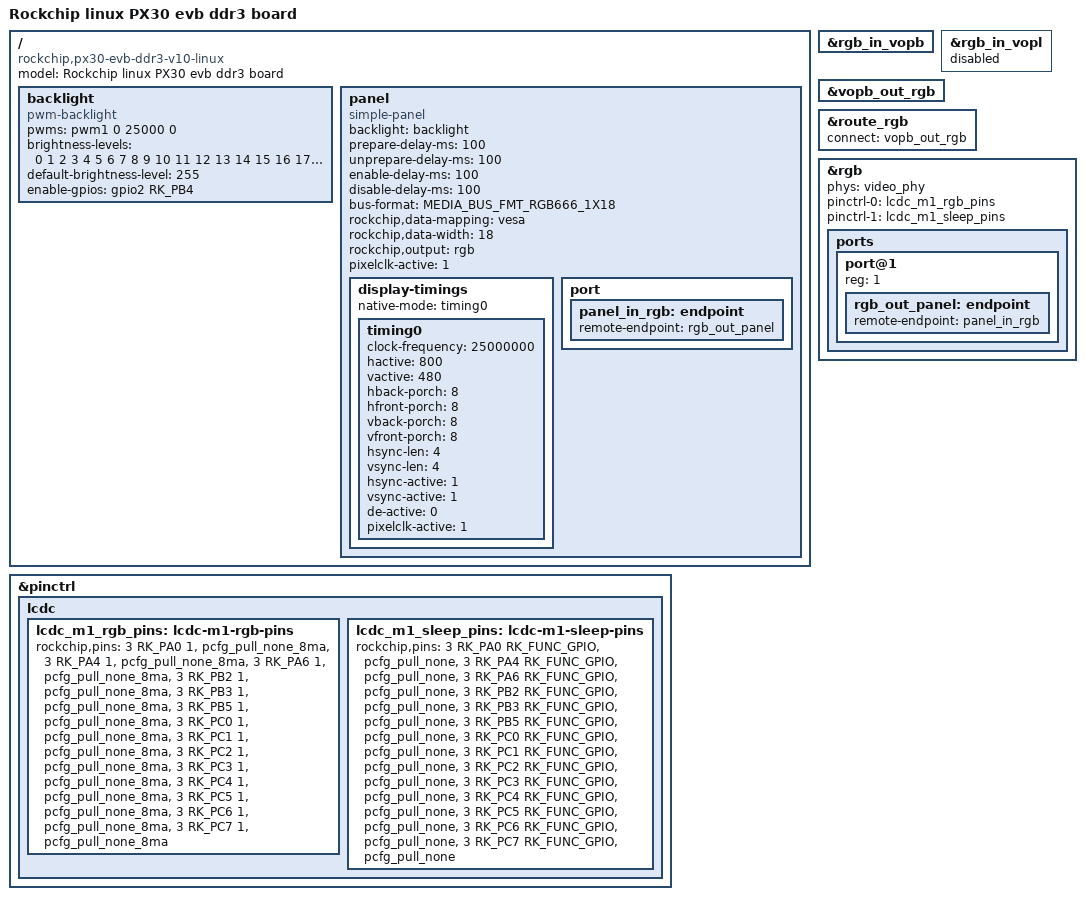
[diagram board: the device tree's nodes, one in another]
// SPDX-License-Identifier: (GPL-2.0+ OR MIT)
/*
 * Copyright (c) 2021 Fuzhou Rockchip Electronics Co., Ltd
 */

/ {
	model = "Rockchip linux PX30 evb ddr3 board";
	compatible = "rockchip,px30-evb-ddr3-v10-linux", "rockchip,px30";

	/delete-node/ test-power;

    backlight: backlight {
        compatible = "pwm-backlight";
        pwms = <&pwm1 0 25000 0>;
        brightness-levels = <
              0   1   2   3   4   5   6   7
              8   9  10  11  12  13  14  15
             16  17  18  19  20  21  22  23
             24  25  26  27  28  29  30  31
             32  33  34  35  36  37  38  39
             40  41  42  43  44  45  46  47
             48  49  50  51  52  53  54  55
             56  57  58  59  60  61  62  63
             64  65  66  67  68  69  70  71
             72  73  74  75  76  77  78  79
             80  81  82  83  84  85  86  87
             88  89  90  91  92  93  94  95
             96  97  98  99 100 101 102 103
            104 105 106 107 108 109 110 111
            112 113 114 115 116 117 118 119
            120 121 122 123 124 125 126 127
            128 129 130 131 132 133 134 135
            136 137 138 139 140 141 142 143
            144 145 146 147 148 149 150 151
            152 153 154 155 156 157 158 159
            160 161 162 163 164 165 166 167
            168 169 170 171 172 173 174 175
            176 177 178 179 180 181 182 183
            184 185 186 187 188 189 190 191
            192 193 194 195 196 197 198 199
            200 201 202 203 204 205 206 207
            208 209 210 211 212 213 214 215
            216 217 218 219 220 221 222 223
            224 225 226 227 228 229 230 231
            232 233 234 235 236 237 238 239
            240 241 242 243 244 245 246 247
            248 249 250 251 252 253 254 255>;
        default-brightness-level = <255>;
        enable-gpios = <&gpio2 RK_PB4 GPIO_ACTIVE_HIGH>;
    };

	//-----------------------RK050HR18-----------------------------
	 panel:panel {
	 	status = "okay";
	 	compatible ="simple-panel";
	 	backlight = <&backlight>;
	 	//enable-gpios = <&gpio0 RK_PC0 GPIO_ACTIVE_LOW>;
	 	//reset-gpios = <&gpio3 RK_PD1 GPIO_ACTIVE_LOW>;
	 	prepare-delay-ms = <100>;
	 	unprepare-delay-ms = <100>;
	 	enable-delay-ms = <100>;
	 	disable-delay-ms = <100>;
	 	bus-format = <MEDIA_BUS_FMT_RGB666_1X18>;
	 	rockchip,data-mapping = "vesa";
	 	rockchip,data-width = <18>;
	 	rockchip,output = "rgb";
	 	pixelclk-active = <1>;

	 	display-timings {
	 		native-mode = <&timing0>;

	 		timing0: timing0 {
	 			clock-frequency = <25000000>;
	 			hactive = <800>;
	 			vactive = <480>;
	 			hback-porch = <8>;
	 			hfront-porch = <8>;
	 			vback-porch = <8>;
	 			vfront-porch = <8>;
	 			hsync-len = <4>;
	 			vsync-len = <4>;
	 			hsync-active = <1>;
	 			vsync-active = <1>;
	 			de-active = <0>;
	 			pixelclk-active = <1>;
	 		};
	 	};

	 	port {
	 		panel_in_rgb: endpoint {
	 			remote-endpoint = <&rgb_out_panel>;
	 		};
	 	};
	 };

	//-----------------------RK050HR18-----------------------------
};

&rgb_in_vopb{
	status = "okay";
};

&rgb_in_vopl{
	status = "disabled";
};

&vopb_out_rgb {
	status = "okay";
};

&route_rgb {                   
    connect = <&vopb_out_rgb>;
    status = "okay";
};

&rgb {
	status = "okay";
    phys = <&video_phy>;
    phy-names = "phy";
    pinctrl-names = "default", "sleep";
    pinctrl-0 = <&lcdc_m1_rgb_pins>;
    pinctrl-1 = <&lcdc_m1_sleep_pins>;

	ports {
		port@1 {
			reg = <1>;

			rgb_out_panel: endpoint {              
				remote-endpoint = <&panel_in_rgb>;
			};
		};
	};
};

&pinctrl {
    lcdc {
        lcdc_m1_rgb_pins: lcdc-m1-rgb-pins {
            rockchip,pins =
                <3 RK_PA0 1 &pcfg_pull_none_8ma>,   /* LCDC_DCLK */
                <3 RK_PA4 1 &pcfg_pull_none_8ma>,   /* LCDC_D0 */
                <3 RK_PA6 1 &pcfg_pull_none_8ma>,   /* LCDC_D2 */
                <3 RK_PB2 1 &pcfg_pull_none_8ma>,   /* LCDC_D6 */
                <3 RK_PB3 1 &pcfg_pull_none_8ma>,   /* LCDC_D7 */
                <3 RK_PB5 1 &pcfg_pull_none_8ma>,   /* LCDC_D9 */
                <3 RK_PC0 1 &pcfg_pull_none_8ma>,   /* LCDC_D12 */
                <3 RK_PC1 1 &pcfg_pull_none_8ma>,   /* LCDC_D13 */
                <3 RK_PC2 1 &pcfg_pull_none_8ma>,   /* LCDC_D14 */
                <3 RK_PC3 1 &pcfg_pull_none_8ma>,   /* LCDC_D15 */
                <3 RK_PC4 1 &pcfg_pull_none_8ma>,   /* LCDC_D16 */
                <3 RK_PC5 1 &pcfg_pull_none_8ma>,   /* LCDC_D17 */
                <3 RK_PC6 1 &pcfg_pull_none_8ma>,   /* LCDC_D18 */
                <3 RK_PC7 1 &pcfg_pull_none_8ma>;   /* LCDC_D19 */
//                <3 RK_PD0 1 &pcfg_pull_none_8ma>,   /* LCDC_D20 */
//                <3 RK_PD1 1 &pcfg_pull_none_8ma>,   /* LCDC_D21 */
//                <3 RK_PD2 1 &pcfg_pull_none_8ma>,   /* LCDC_D22 */
//                <3 RK_PD3 1 &pcfg_pull_none_8ma>;   /* LCDC_D23 */
        };

        lcdc_m1_sleep_pins: lcdc-m1-sleep-pins {
            rockchip,pins =
                <3 RK_PA0 RK_FUNC_GPIO &pcfg_pull_none>,    /* LCDC_DCLK */
                <3 RK_PA4 RK_FUNC_GPIO &pcfg_pull_none>,    /* LCDC_D0 */
                <3 RK_PA6 RK_FUNC_GPIO &pcfg_pull_none>,    /* LCDC_D2 */
                <3 RK_PB2 RK_FUNC_GPIO &pcfg_pull_none>,    /* LCDC_D6 */
                <3 RK_PB3 RK_FUNC_GPIO &pcfg_pull_none>,    /* LCDC_D7 */
                <3 RK_PB5 RK_FUNC_GPIO &pcfg_pull_none>,    /* LCDC_D9 */
                <3 RK_PC0 RK_FUNC_GPIO &pcfg_pull_none>,    /* LCDC_D12 */
                <3 RK_PC1 RK_FUNC_GPIO &pcfg_pull_none>,    /* LCDC_D13 */
                <3 RK_PC2 RK_FUNC_GPIO &pcfg_pull_none>,    /* LCDC_D14 */
                <3 RK_PC3 RK_FUNC_GPIO &pcfg_pull_none>,    /* LCDC_D15 */
                <3 RK_PC4 RK_FUNC_GPIO &pcfg_pull_none>,    /* LCDC_D16 */
                <3 RK_PC5 RK_FUNC_GPIO &pcfg_pull_none>,    /* LCDC_D17 */
                <3 RK_PC6 RK_FUNC_GPIO &pcfg_pull_none>,    /* LCDC_D20 */
                <3 RK_PC7 RK_FUNC_GPIO &pcfg_pull_none>;    /* LCDC_D19 */
//                <3 RK_PD0 RK_FUNC_GPIO &pcfg_pull_none>,    /* LCDC_D20 */
//                <3 RK_PD1 RK_FUNC_GPIO &pcfg_pull_none>,    /* LCDC_D21 */
//                <3 RK_PD2 RK_FUNC_GPIO &pcfg_pull_none>,    /* LCDC_D22 */
//                <3 RK_PD3 RK_FUNC_GPIO &pcfg_pull_none>;    /* LCDC_D23 */
        };
    };
};
